VERSION ""

NS_ :

BS_:

BU_: MCU HCU

BO_ 3221225472 VECTOR__INDEPENDENT_SIG_MSG: 0 Vector__XXX
 SG_ uuuu : 0|16@1+ (1,0) [0|0] "" Vector__XXX
 SG_ HCU_TM_Check_Sum : 0|8@1+ (1,0) [0|255] "" Vector__XXX
 SG_ HCU_ISG_Check_Sum : 0|8@1+ (1,0) [0|255] "" Vector__XXX
 SG_ HCU_TM_Live_Counter : 0|4@1+ (1,0) [0|15] "" Vector__XXX
 SG_ HCU_ISG_Live_Counter : 0|4@1+ (1,0) [0|15] "" Vector__XXX
 SG_ TM_Hardware_Error_Code_5 : 0|8@1+ (1,0) [0|0] "" Vector__XXX
 SG_ ISG_Live_counter4 : 0|4@1+ (1,0) [0|0] "" Vector__XXX
 SG_ ISG_Hardware_Error_Code_5 : 0|8@1+ (1,0) [0|0] "" Vector__XXX

BO_ 2365526255 New_Message_11: 8 Vector__XXX
 SG_ Slide_enable : 0|8@1+ (1,0) [0|0] "" Vector__XXX

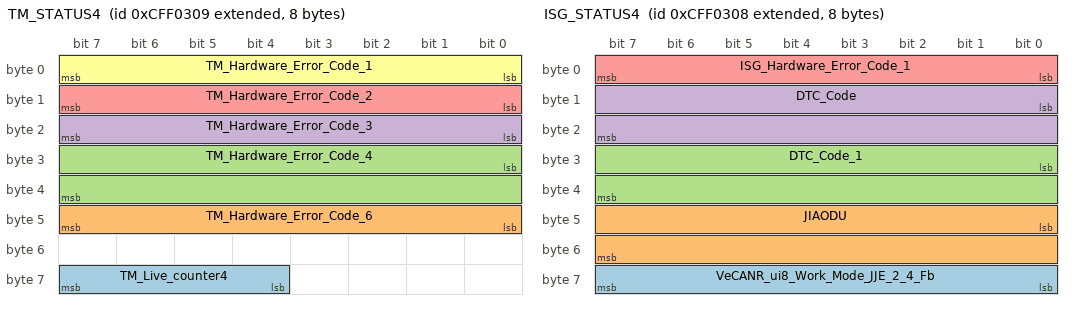
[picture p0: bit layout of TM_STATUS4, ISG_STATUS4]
BO_ 2365522697 TM_STATUS4: 8 MCU
 SG_ TM_Live_counter4 : 60|4@1+ (1,0) [0|0] ""  HCU
 SG_ TM_Hardware_Error_Code_6 : 40|8@1+ (1,0) [0|0] ""  HCU
 SG_ TM_Hardware_Error_Code_4 : 24|16@1+ (1,0) [0|0] ""  HCU
 SG_ TM_Hardware_Error_Code_3 : 16|8@1+ (1,0) [0|0] ""  HCU
 SG_ TM_Hardware_Error_Code_2 : 8|8@1+ (1,0) [0|0] ""  HCU
 SG_ TM_Hardware_Error_Code_1 : 0|8@1+ (1,0) [0|0] ""  HCU

BO_ 2365522696 ISG_STATUS4: 8 MCU
 SG_ VeCANR_ui8_Work_Mode_JJE_2_4_Fb : 56|8@1+ (1,0) [0|0] ""  HCU
 SG_ JIAODU : 40|16@1+ (1,0) [0|0] ""  HCU
 SG_ DTC_Code_1 : 24|16@1+ (1,0) [0|0] ""  HCU
 SG_ DTC_Code : 8|16@1+ (1,0) [0|0] ""  HCU
 SG_ ISG_Hardware_Error_Code_1 : 0|8@1+ (1,0) [0|0] "" Vector__XXX

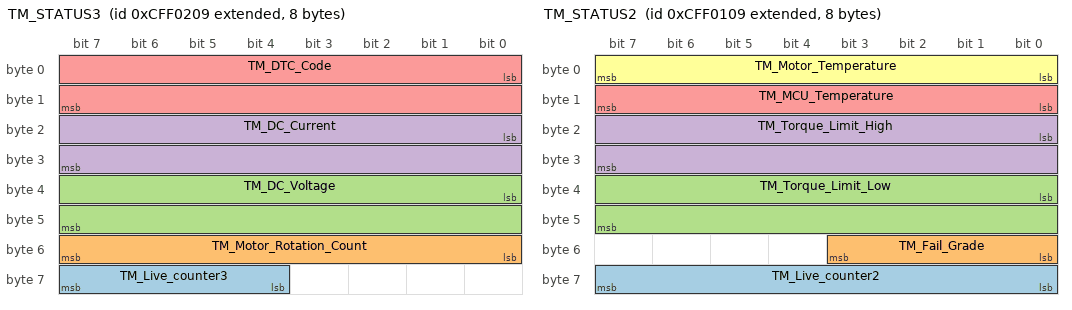
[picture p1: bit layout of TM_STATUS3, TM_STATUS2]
BO_ 2365522441 TM_STATUS3: 8 MCU
 SG_ TM_Live_counter3 : 60|4@1+ (1,0) [0|15] ""  HCU
 SG_ TM_Motor_Rotation_Count : 48|8@1+ (1,0) [0|255] ""  HCU
 SG_ TM_DC_Voltage : 32|16@1+ (0.1,0) [0|1000] "V"  HCU
 SG_ TM_DC_Current : 16|16@1+ (1,-1000) [-1000|64535] "A"  HCU
 SG_ TM_DTC_Code : 0|16@1+ (1,0) [0|0] ""  HCU

BO_ 2365522185 TM_STATUS2: 8 MCU
 SG_ TM_Live_counter2 : 56|8@1+ (1,0) [0|255] ""  HCU
 SG_ TM_Fail_Grade : 48|4@1+ (1,0) [0|4] ""  HCU
 SG_ TM_Torque_Limit_Low : 32|16@1+ (1,-5000) [-5000|60535] "Nm"  HCU
 SG_ TM_Torque_Limit_High : 16|16@1+ (1,0) [0|5000] "Nm"  HCU
 SG_ TM_MCU_Temperature : 8|8@1+ (1,-40) [-40|215] "degree Celsius"  HCU
 SG_ TM_Motor_Temperature : 0|8@1+ (1,-40) [-40|215] "degree Celsius"  HCU

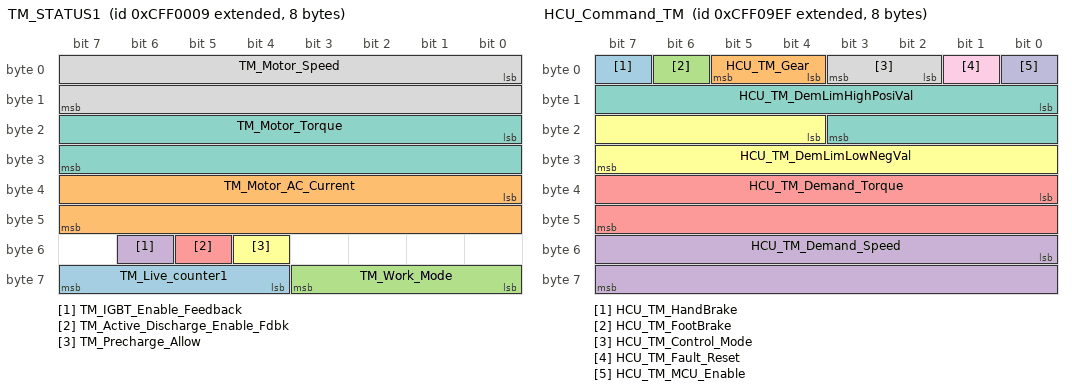
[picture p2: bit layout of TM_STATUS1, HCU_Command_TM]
BO_ 2365521929 TM_STATUS1: 8 MCU
 SG_ TM_Live_counter1 : 60|4@1+ (1,0) [0|15] ""  HCU
 SG_ TM_Motor_AC_Current : 32|16@1+ (0.1,0) [0|1000] ""  HCU
 SG_ TM_Work_Mode : 56|4@1+ (1,0) [0|15] ""  HCU
 SG_ TM_IGBT_Enable_Feedback : 54|1@1+ (1,0) [0|1] ""  HCU
 SG_ TM_Active_Discharge_Enable_Fdbk : 53|1@1+ (1,0) [0|1] ""  HCU
 SG_ TM_Precharge_Allow : 52|1@1+ (1,0) [0|1] ""  HCU
 SG_ TM_Motor_Torque : 16|16@1+ (1,-5000) [-5000|60535] "Nm"  HCU
 SG_ TM_Motor_Speed : 0|16@1+ (1,-15000) [-15000|50535] "rpm"  HCU

BO_ 2365524463 HCU_Command_TM: 8 HCU
 SG_ HCU_TM_HandBrake : 7|1@1+ (1,0) [0|0] ""  MCU
 SG_ HCU_TM_Gear : 4|2@1+ (1,0) [0|0] ""  MCU
 SG_ HCU_TM_FootBrake : 6|1@1+ (1,0) [0|0] ""  MCU
 SG_ HCU_TM_Demand_Speed : 48|16@1+ (1,-15000) [-15000|50535] "rpm"  MCU
 SG_ HCU_TM_Demand_Torque : 32|16@1+ (1,-5000) [-5000|60535] "Nm"  MCU
 SG_ HCU_TM_DemLimLowNegVal : 20|12@1+ (4,0) [0|16380] "Nm/rpm"  MCU
 SG_ HCU_TM_DemLimHighPosiVal : 8|12@1+ (4,0) [0|16380] "Nm/rpm"  MCU
 SG_ HCU_TM_Control_Mode : 2|2@1+ (1,0) [0|3] ""  MCU
 SG_ HCU_TM_Fault_Reset : 1|1@1+ (1,0) [0|1] ""  MCU
 SG_ HCU_TM_MCU_Enable : 0|1@1+ (1,0) [0|1] ""  MCU

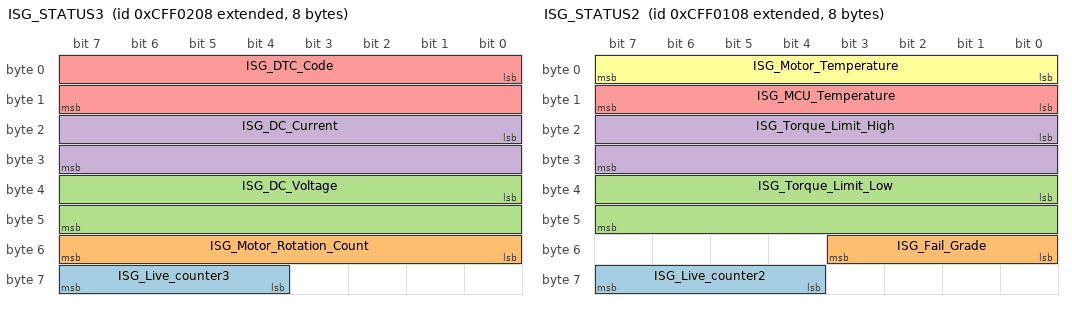
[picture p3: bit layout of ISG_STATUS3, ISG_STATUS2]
BO_ 2365522440 ISG_STATUS3: 8 MCU
 SG_ ISG_Live_counter3 : 60|4@1+ (1,0) [0|15] ""  HCU
 SG_ ISG_Motor_Rotation_Count : 48|8@1+ (1,0) [0|255] ""  HCU
 SG_ ISG_DC_Voltage : 32|16@1+ (0.1,0) [0|1000] "V"  HCU
 SG_ ISG_DC_Current : 16|16@1+ (1,-1000) [-1000|64535] "A"  HCU
 SG_ ISG_DTC_Code : 0|16@1+ (1,0) [0|0] ""  HCU

BO_ 2365522184 ISG_STATUS2: 8 MCU
 SG_ ISG_Live_counter2 : 60|4@1+ (1,0) [0|15] ""  HCU
 SG_ ISG_Fail_Grade : 48|4@1+ (1,0) [0|4] ""  HCU
 SG_ ISG_Torque_Limit_Low : 32|16@1+ (1,-5000) [-5000|60535] "Nm"  HCU
 SG_ ISG_Torque_Limit_High : 16|16@1+ (1,0) [0|5000] "Nm"  HCU
 SG_ ISG_MCU_Temperature : 8|8@1+ (1,-40) [-40|215] "degree Celsius"  HCU
 SG_ ISG_Motor_Temperature : 0|8@1+ (1,-40) [-40|215] "degree Celsius"  HCU

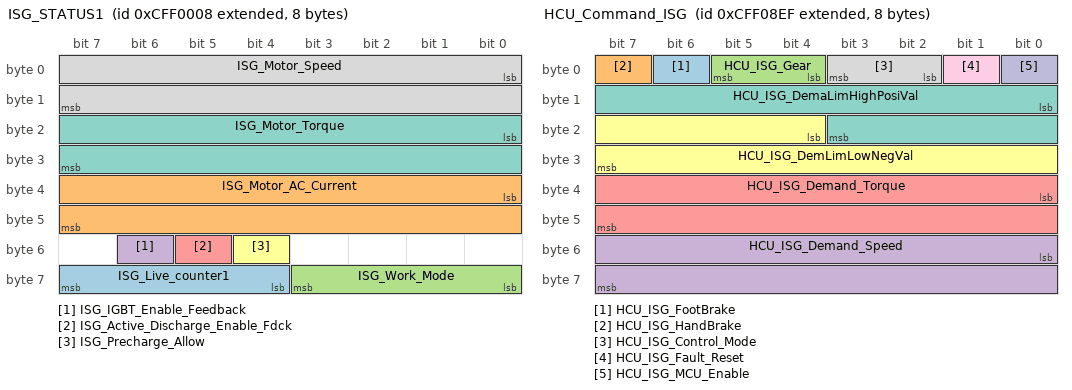
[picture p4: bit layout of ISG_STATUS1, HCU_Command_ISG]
BO_ 2365521928 ISG_STATUS1: 8 MCU
 SG_ ISG_Live_counter1 : 60|4@1+ (1,0) [0|15] ""  HCU
 SG_ ISG_Motor_AC_Current : 32|16@1- (0.1,0) [-3276.8|3276.7] ""  HCU
 SG_ ISG_Work_Mode : 56|4@1+ (1,0) [0|15] ""  HCU
 SG_ ISG_IGBT_Enable_Feedback : 54|1@1+ (1,0) [0|1] ""  HCU
 SG_ ISG_Active_Discharge_Enable_Fdck : 53|1@1+ (1,0) [0|1] ""  HCU
 SG_ ISG_Precharge_Allow : 52|1@1+ (1,0) [0|1] ""  HCU
 SG_ ISG_Motor_Torque : 16|16@1+ (1,-5000) [-5000|60535] "Nm"  HCU
 SG_ ISG_Motor_Speed : 0|16@1+ (1,-15000) [-15000|50535] "rpm"  HCU

BO_ 2365524207 HCU_Command_ISG: 8 HCU
 SG_ HCU_ISG_FootBrake : 6|1@1+ (1,0) [0|0] ""  MCU
 SG_ HCU_ISG_HandBrake : 7|1@1+ (1,0) [0|0] ""  MCU
 SG_ HCU_ISG_Gear : 4|2@1+ (1,0) [0|0] ""  MCU
 SG_ HCU_ISG_Demand_Speed : 48|16@1+ (1,-15000) [-15000|50535] "rpm"  MCU
 SG_ HCU_ISG_Demand_Torque : 32|16@1+ (1,-5000) [-5000|60535] "Nm"  MCU
 SG_ HCU_ISG_DemLimLowNegVal : 20|12@1+ (4,0) [0|16380] "Nm/rpm"  MCU
 SG_ HCU_ISG_DemaLimHighPosiVal : 8|12@1+ (4,0) [0|16380] "Nm/rpm"  MCU
 SG_ HCU_ISG_Control_Mode : 2|2@1+ (1,0) [0|3] ""  MCU
 SG_ HCU_ISG_Fault_Reset : 1|1@1+ (1,0) [0|1] ""  MCU
 SG_ HCU_ISG_MCU_Enable : 0|1@1+ (1,0) [0|1] ""  MCU

CM_ BO_ 3221225472 "This is a message for not used signals, created by Vector CANdb++ DBC OLE DB Provider.";
CM_ BO_ 2365522441 "Period 20ms";
CM_ BO_ 2365522185 "Period 20ms";
CM_ SG_ 2365522185 TM_Fail_Grade "0 = No Fault
1 = Warning(degraded)
2 = Fault(zero torque output)
3 = Fault(shut down MCU)
4 = Serious Fault(need to stop the vehicle)";
CM_ SG_ 2365522185 TM_Torque_Limit_Low "转矩下限";
CM_ BO_ 2365521929 "Period 20ms";
CM_ SG_ 2365521929 TM_Work_Mode "0 = INIT
1 = LV_PWR_UP
2 = HV_PWR_UP
3 = Idle
4 = Speed Control
5 = Torque Control
6 = SHUTDWN(active capacitor discharge)
7 = LV_PWR_DWN
8 = FAULT";
CM_ SG_ 2365521929 TM_IGBT_Enable_Feedback "0 = disable
1 = enable";
CM_ SG_ 2365521929 TM_Active_Discharge_Enable_Fdbk "0 = disable
1 = enable";
CM_ SG_ 2365521929 TM_Precharge_Allow "0 = disable
1 = enable";
CM_ SG_ 2365521929 TM_Motor_Torque "转矩矩大于0为转矩方向与发动机转向相同";
CM_ SG_ 2365521929 TM_Motor_Speed "电机转速正负表示电机转向，转速为正时与发动机正常转动方向一致";
CM_ BO_ 2365524463 "Period 20ms";
CM_ SG_ 2365524463 HCU_TM_HandBrake "0;未拉手刹
1：拉手刹";
CM_ SG_ 2365524463 HCU_TM_Gear "00:空档位
01：前进档位
10：后退档位";
CM_ SG_ 2365524463 HCU_TM_FootBrake "0:未踩脚刹
1：踩脚刹";
CM_ SG_ 2365524463 HCU_TM_DemLimLowNegVal "4X Toruqe, 1X Speed, Transmited Positive Value, Physical negative value";
CM_ SG_ 2365524463 HCU_TM_DemLimHighPosiVal "4X Toruqe, 1X Speed";
CM_ SG_ 2365524463 HCU_TM_Control_Mode "0 = Standby
1 = Speed Control
2 = Torque Control
3 = Active Discharge";
CM_ SG_ 2365524463 HCU_TM_Fault_Reset "0 = disable
1 = enable";
CM_ SG_ 2365524463 HCU_TM_MCU_Enable "0 = disable
1 = enable";
CM_ BO_ 2365522440 "Period 20ms";
CM_ BO_ 2365522184 "Period 20ms";
CM_ SG_ 2365522184 ISG_Fail_Grade "0 = No Fault
1 = Warning(degraded)
2 = Fault(zero torque output)
3 = Fault(shut down MCU)
4 = Serious Fault(need to stop the vehicle)";
CM_ SG_ 2365522184 ISG_Torque_Limit_Low "转矩下限";
CM_ BO_ 2365521928 "Period 20ms";
CM_ SG_ 2365521928 ISG_Work_Mode "0 = INIT
1 = LV_PWR_UP
2 = HV_PWR_UP
3 = Idle
4 = Speed Control
5 = Torque Control
6 = SHUTDWN(active capacitor discharge)
7 = LV_PWR_DWN
8 = FAULT";
CM_ SG_ 2365521928 ISG_IGBT_Enable_Feedback "0 = disable
1 = enable";
CM_ SG_ 2365521928 ISG_Active_Discharge_Enable_Fdck "0 = disable
1 = enable";
CM_ SG_ 2365521928 ISG_Precharge_Allow "0 = disable
1 = enable";
CM_ SG_ 2365521928 ISG_Motor_Torque "转矩矩大于0为转矩方向与发动机转向相同";
CM_ SG_ 2365521928 ISG_Motor_Speed "电机转速正负表示电机转向，转速为正时与发动机正常转动方向一致";
CM_ BO_ 2365524207 "Period 20ms";
CM_ SG_ 2365524207 HCU_ISG_FootBrake "0:未踩脚刹
1：踩脚刹";
CM_ SG_ 2365524207 HCU_ISG_HandBrake "0;未拉手刹
1：拉手刹";
CM_ SG_ 2365524207 HCU_ISG_Gear "00:空档位
01：前进档位
10：后退档位";
CM_ SG_ 2365524207 HCU_ISG_DemLimLowNegVal "4X Toruqe, 1X Speed";
CM_ SG_ 2365524207 HCU_ISG_DemaLimHighPosiVal "4X Toruqe, 1X Speed";
CM_ SG_ 2365524207 HCU_ISG_Control_Mode "0 = Standby
1 = Speed Control
2 = Torque Control
3 = Active Discharge";
CM_ SG_ 2365524207 HCU_ISG_Fault_Reset "0 = disable
1 = enable";
CM_ SG_ 2365524207 HCU_ISG_MCU_Enable "0 = disable
1 = enable";
